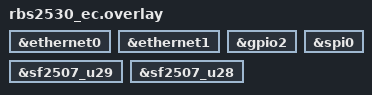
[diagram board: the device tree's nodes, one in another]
&ethernet0 {
	status = "okay";
};

&ethernet1 {
	status = "okay";
};

&gpio2 {
	status = "okay";
};

&spi0 {
	status = "okay";
};

&sf2507_u29 {
	status = "okay";
};

&sf2507_u28 {
	status = "okay";
};
